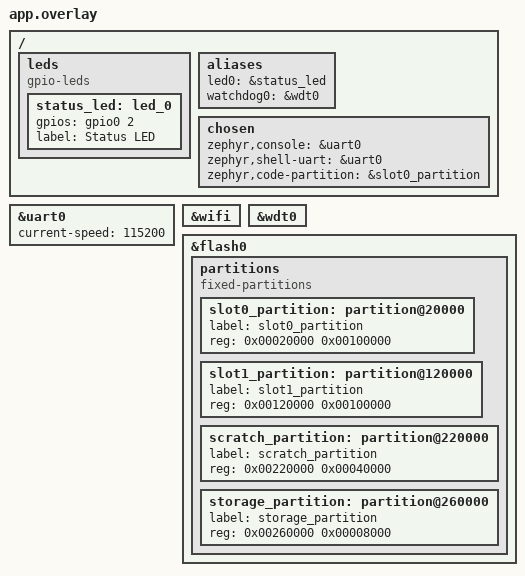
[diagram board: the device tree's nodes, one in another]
/*
 * Application-specific hardware configuration and flash layout.
 * The flash partition map here MUST match the one in the .yml file.
 */
/ {
    /* Board-specific hardware customization for your application */
    leds {
        compatible = "gpio-leds";
        status_led: led_0 {
            gpios = <&gpio0 2 GPIO_ACTIVE_HIGH>;
            label = "Status LED";
        };
    };

    aliases {
        led0 = &status_led;
        watchdog0 = &wdt0;
    };

    chosen {
        zephyr,console = &uart0;
        zephyr,shell-uart = &uart0;
        zephyr,code-partition = &slot0_partition; /* Tells Zephyr where the app runs */
    };
};

&uart0 {
    status = "okay";
    current-speed = <115200>;
};

&wifi {
    status = "okay";
};

&wdt0 {
    status = "okay";
};

/* Flash partitioning for OTA. MUST MATCH partitions.yml */
&flash0 {
    partitions {
        compatible = "fixed-partitions";
        #address-cells = <1>;
        #size-cells = <1>;

        slot0_partition: partition@20000 {
            label = "slot0_partition";
            reg = <0x00020000 0x00100000>;
        };

        slot1_partition: partition@120000 {
            label = "slot1_partition";
            reg = <0x00120000 0x00100000>;
        };

        scratch_partition: partition@220000 {
            label = "scratch_partition";
            reg = <0x00220000 0x00040000>;
        };

        storage_partition: partition@260000 {
            label = "storage_partition";
            reg = <0x00260000 0x00008000>;
        };
    };
};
